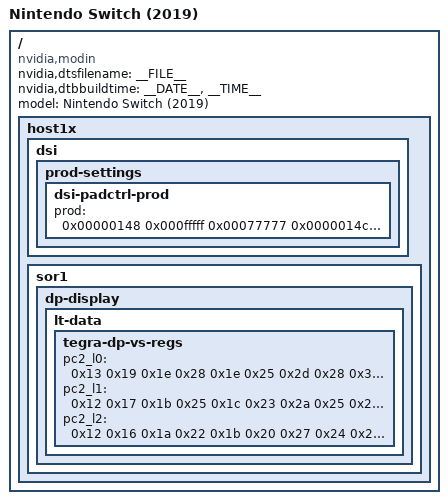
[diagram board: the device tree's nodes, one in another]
/*
 * Copyright (c) 2022, CTCaer <ctcaer@gmail.com>
 *
 * This program is free software; you can redistribute it and/or modify
 * it under the terms of the GNU General Public License as published by
 * the Free Software Foundation; version 2 of the License.
 *
 * This program is distributed in the hope that it will be useful, but WITHOUT
 * ANY WARRANTY; without even the implied warranty of MERCHANTABILITY or
 * FITNESS FOR A PARTICULAR PURPOSE.  See the GNU General Public License for
 * more details.
 *
 */

#include "nx-platforms/tegra210b01-nx-common.dtsi"
#include "nx-platforms/tegra210b01-modin-gpio.dtsi"
#include "nx-platforms/tegra210b01-modin-pinmux.dtsi"
#include "nx-platforms/tegra210-nx-common-disp.dtsi"
#include "nx-platforms/tegra210b01-modin-power-tree.dtsi"
#include "nx-platforms/tegra210-nx-sensor.dtsi"

/ {
	nvidia,dtsfilename = __FILE__;
	nvidia,dtbbuildtime = __DATE__, __TIME__;

	model = "Nintendo Switch (2019)";
	compatible = "nvidia,modin", "nvidia,odin", "nintendo,iowa", "nintendo,nx", "nvidia,tegra210b01";

	host1x {
		dsi {
			prod-settings {
				#prod-cells = <3>;
				dsi-padctrl-prod {
					prod = <
						0x00000148 0x000fffff 0x00077777	/* PAD_CONTROL_4 */
						0x0000014c 0x000fffff 0x00077777	/* PAD_CONTROL_5 */
						0x00000150 0x00003333 0x00001111	/* PAD_CONTROL_6 */
						>;
				};
			};
		};

		sor1 {
			dp-display {
				lt-data {
					tegra-dp-vs-regs {
						/* postcursor2 L0 */
						pc2_l0 = <
							/* pre-emphasis: L0, L1, L2, L3 */
							0x13 0x19 0x1e 0x28 /* voltage swing: L0 */
							0x1e 0x25 0x2d /* L1 */
							0x28 0x32 /* L2 */
							0x39 /* L3 */
						>;
						/* postcursor2 L1 */
						pc2_l1 = <
							0x12 0x17 0x1b 0x25
							0x1c 0x23 0x2a
							0x25 0x2f
							0x37
						>;
						/* postcursor2 L2 */
						pc2_l2 = <
							0x12 0x16 0x1a 0x22
							0x1b 0x20 0x27
							0x24 0x2d
							0x35
						>;
					};
				};
			};
		};
	};
};
